# EFR32BG22C112F352GM40 register map
Vendor: Silicon Labs; Series: EFR32; File version: C
Registers are 32-bit, read-write, reset 0x0 unless marked. A register's access mark holds for its fields unless they carry their own. Offsets are from the block's base; [hi:lo] are bit positions.

## RFSENSE_S — RFSENSE_S Registers
Base 0x4009C000
Same registers: RFSENSE_NS 0x5009C000
0x00 EN — Block enables
  [0] EN — RFSENSE Enable
0x04 EM4WUEN
  [0] EM4WUEN — EM4 WakeUp Enable
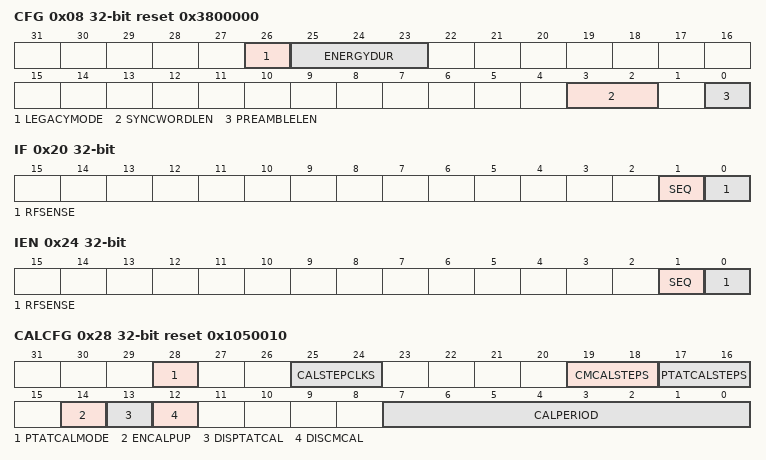
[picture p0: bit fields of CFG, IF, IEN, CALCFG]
0x08 CFG reset 0x3800000 — Configures RFSENSE digital logic behavior
  [26] LEGACYMODE — RFSENSE Legacy Mode
  [25:23] ENERGYDUR — RFSENSE Energy Duration
    0=dur1ms (1ms duration); 1=dur2ms (2ms duration); 2=dur4ms (4ms duration); 3=dur8ms (8ms duration); 4=dur16ms (16ms duration); 5=dur32ms (32ms duration); 6=dur64ms (64ms duration); 7=dur128ms (128ms duration)
  [3:2] SYNCWORDLEN — Synword Length
  [0] PREAMBLELEN — Number of Preamble bits
0x0C SYNCWORD
0x10 THDSEL reset 0x80
  [7:0] THDSEL — Threshold Select
0x20 IF
  [1] SEQ — Sequencer Interrupt Flag
  [0] RFSENSE — RFSENSE Interrupt Flag
0x24 IEN
  [1] SEQ — Sequencer Interrupt Enable
  [0] RFSENSE — RFSENSE Interrrupt Enable
0x28 CALCFG reset 0x1050010
  [28] PTATCALMODE — PTAT Calibration mode
  [25:24] CALSTEPCLKS — Clocks per calibration step settling
  [19:18] CMCALSTEPS — CM Calibration Steps
    0=STEPS2; 1=STEPS4; 2=STEPS6; 3=STEPS8
  [17:16] PTATCALSTEPS — PTAT Calibration Steps
    0=STEPS2; 1=STEPS4; 2=STEPS6; 3=STEPS8
  [14] ENCALPUP — Enable Calibration at Power Up
  [13] DISPTATCAL — Disable PTAT Calibration
  [12] DISCMCAL — Disable Common Mode Calibration
  [7:0] CALPERIOD — Calibration Period
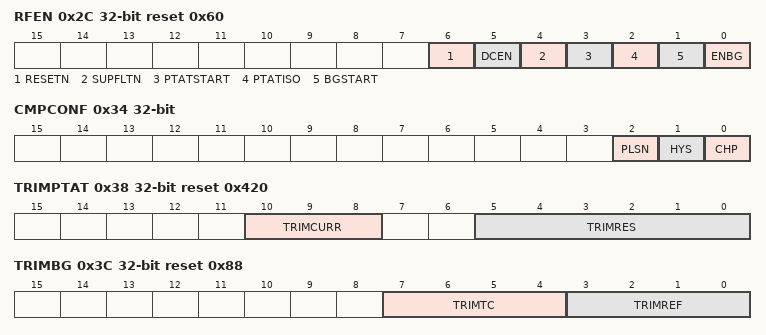
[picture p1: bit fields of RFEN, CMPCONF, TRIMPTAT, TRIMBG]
0x2C RFEN reset 0x60
  [6] RESETN — Reset RFSENSE data flop
  [5] DCEN — DC Bias Enable
  [4] SUPFLTN — Disable supply filtering
  [3] PTATSTART — PTAT Startup signal
  [2] PTATISO — Isolate PTAT core
  [1] BGSTART — Bandgap Startup Signal
  [0] ENBG — Enable Bandgap
0x30 MODESEL
  [2:0] MODESEL — Mode Select
    0=NORMAL_OP (Normal operation); 1=CM_CAL (Common-mode calibration); 2=REF_CAL (Bandgap Reference calibration); 3=NORMAL_OP2 (Normal operation mode-2); 4=DM_A_CAL (Differntial A calibration); 5=DM_B_CAL (Differential B calibration); 6=DM_A_CAL2 (Differential A mode-2 calibration); 7=DM_B_CAL2 (Differential B mode-2 calibration)
0x34 CMPCONF
  [2] PLSN — Disable Comparator reset pulse
  [1] HYS — Enable Hysteresis
  [0] CHP — Invert Comparator IO
0x38 TRIMPTAT reset 0x420 — IPTAT Calbiration trim values
  [10:8] TRIMCURR — PTAT current trim
    0=m80pct (Reduce PTAT current by 80%); 1=m60pct (Reduce PTAT current by 60%); 2=m40pct (Reduce PTAT current by 40%); 3=m20pct (Reduce PTAT current by 20%); 4=Default PTAT current; 5=p20pct (Increase PTAT current by 20%); 6=p40pct (Increase PTAT current by 40%); 7=p60pct (Increase PTAT current by 60%)
  [5:0] TRIMRES — PTAT reference resistor trim
0x3C TRIMBG reset 0x88 — BandGap Calibration trim values
  [7:4] TRIMTC — TempCo Trim
  [3:0] TRIMREF — Reference Trim
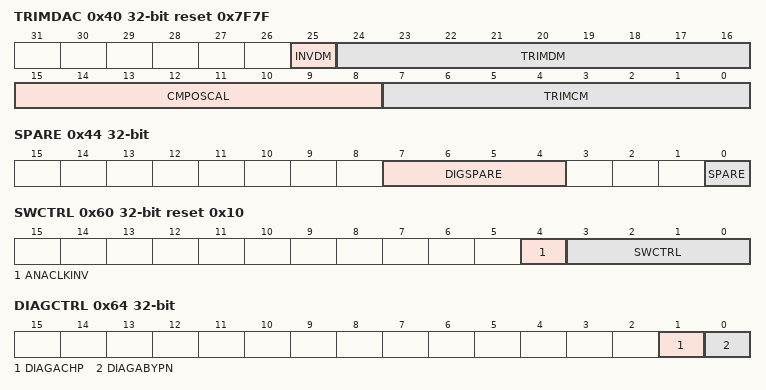
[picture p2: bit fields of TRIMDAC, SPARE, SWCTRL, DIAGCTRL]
0x40 TRIMDAC reset 0x7F7F — RFSENSE DAC trim values
  [25] INVDM — Invert Differential offset polarity
  [24:16] TRIMDM — Trim Differential Mode
  [15:8] CMPOSCAL — Comparator Offset Calibration value
  [7:0] TRIMCM — Trim Common Mode
0x44 SPARE
  [7:4] DIGSPARE — Digital Spare registers
  [0] SPARE
0x60 SWCTRL reset 0x10 — Enable Software Control of the FSM signals
  [4] ANACLKINV — Invert Analog clock
  [3:0] SWCTRL — New BitField
0x64 DIAGCTRL
  [1] DIAGACHP — Diag buffer chop
    0=DISABLE (Disable DIAGA buffer chop); 1=ENABLE (Enable DIAGA buffer chop)
  [0] DIAGABYPN — Diag buffer bypass
    0=ENBYPASS (Enable DIAGA buffer bypass); 1=DISBYPASS (Disable DIAGA buffer bypass)
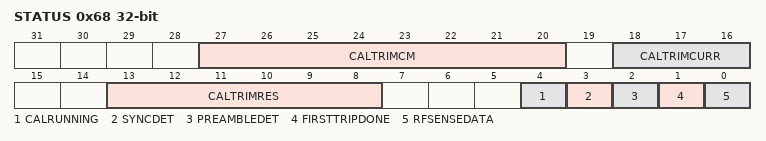
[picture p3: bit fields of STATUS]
0x68 STATUS ro
  [27:20] CALTRIMCM — Calibration Common mode Trim value
  [18:16] CALTRIMCURR — Calibration Current Trim value
  [13:8] CALTRIMRES — Calibration Resistor Trim value
  [4] CALRUNNING — Calibration Running
  [3] SYNCDET — Syncword Detected
  [2] PREAMBLEDET — Preamble Detected
  [1] FIRSTTRIPDONE — First RFSENSE trip done
  [0] RFSENSEDATA — RFSENSE data input from analog
